# neorv32 register map
Vendor: github.com/stnolting/neorv32; Series: RISC-V; File version: 1.13.7
The NEORV32 RISC-V Processor
CPU: other r1p0, little endian, MPU, FPU, I-cache, D-cache, ITCM, DTCM, 4 interrupt priority bits
Address unit: 16 bits
Registers are 32-bit, read-write, reset 0x0 unless marked. A register's access mark holds for its fields unless they carry their own. Offsets are from the block's base; lines under a group give offsets from that group; [hi:lo] are bit positions; {n}, {i} and the like mark numbered series; 'fields as' and 'values as' point back to an identical list; <NAME> marks a mode.

## Memory map
0xFFEA0000 TWD size 0x8 — Two-wire device controller
0xFFEB0000 CFS size 0x10000 — Custom functions subsystem
0xFFEC0000 SLINK size 0x10 — Stream Link Interface
0xFFED0000 DMA size 0x10 — Direct memory access controller
0xFFEF0000 SMC size 0x8 — Serial Memory Controller
0xFFF00000 PWM size 0x100 — Pulse-width modulation controller
0xFFF10000 GPTMR size 0x100 — General purpose timer
0xFFF20000 ONEWIRE size 0x8 — 1-Wire Interface Controller
0xFFF30000 TRACEBUF size 0x10 — Execution Trace Buffer
0xFFF40000 CLINT size 0x10000 — Core local interruptor
0xFFF50000 UART0 size 0x10 — Primary universal asynchronous receiver and transmitter
0xFFF60000 UART1 size 0x10 — Secondary universal asynchronous receiver and transmitter
0xFFF70000 SDI size 0x8 — Serial data interface controller
0xFFF80000 SPI size 0x8 — Serial peripheral interface controller
0xFFF90000 TWI size 0x8 — Two-wire interface controller
0xFFFA0000 TRNG size 0x8 — True random number generator
0xFFFB0000 WDT size 0x8 — Watchdog timer
0xFFFC0000 GPIO size 0x20 — General purpose input/output port
0xFFFD0000 NEOLED size 0x10 — Smart LED hardware interface
0xFFFE0000 SYSINFO size 0x10 — System configuration information memory

## Interrupts
1 CFS_FIRQ (CFS)
2 UART0_FIRQ (UART0)
3 UART1_FIRQ (UART1)
4 TWD_FIRQ (TWD)
5 TRACEBUF_FIRQ (TRACEBUF)
6 SPI_FIRQ (SPI)
7 TWI_FIRQ (TWI)
8 GPIO_FIRQ (GPIO)
9 NEOLED_FIRQ (NEOLED)
10 DMA_FIRQ (DMA)
11 SDI_FIRQ (SDI)
12 GPTMR_FIRQ (GPTMR)
13 ONEWIRE_FIRQ (ONEWIRE)
14 SLINK_FIRQ (SLINK)
15 TRNG_FIRQ (TRNG)

## CFS — Custom functions subsystem
Base 0xFFEB0000
{0x0+4i} REG{i} (i=0..63) — User-defined

## SDI — Serial data interface controller
Base 0xFFF70000
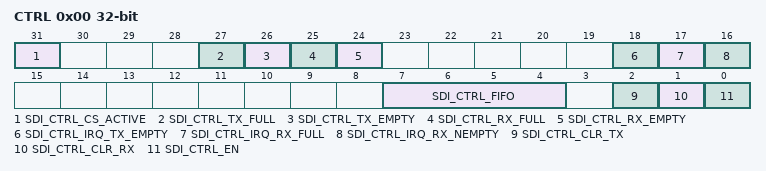
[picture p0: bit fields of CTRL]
0x00 CTRL — Control register
  [31] SDI_CTRL_CS_ACTIVE ro — Chip-select line is active when set
  [27] SDI_CTRL_TX_FULL ro — TX FIFO full
  [26] SDI_CTRL_TX_EMPTY ro — TX FIFO empty
  [25] SDI_CTRL_RX_FULL ro — RX FIFO full
  [24] SDI_CTRL_RX_EMPTY ro — RX FIFO empty
  [18] SDI_CTRL_IRQ_TX_EMPTY — Fire interrupt if TX FIFO is empty
  [17] SDI_CTRL_IRQ_RX_FULL — Fire interrupt if RX FIFO is full
  [16] SDI_CTRL_IRQ_RX_NEMPTY — Fire interrupt if RX FIFO is not empty
  [7:4] SDI_CTRL_FIFO — log2(FIFO size)
  [2] SDI_CTRL_CLR_TX wo — Clear TX FIFO, flag auto-clears
  [1] SDI_CTRL_CLR_RX wo — Clear RX FIFO, flag auto-clears
  [0] SDI_CTRL_EN — SDI enable
0x04 DATA read-modifies — RX/TX data register
  [7:0] SDI_DATA — RX data / TX data (via FIFOs)

## SLINK — Stream Link Interface
Base 0xFFEC0000
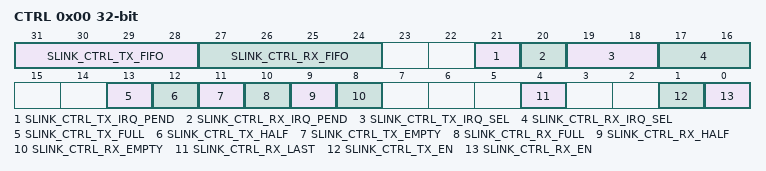
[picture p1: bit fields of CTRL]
0x00 CTRL — Control and status register
  [31:28] SLINK_CTRL_TX_FIFO ro — log2(TX FIFO size)
  [27:24] SLINK_CTRL_RX_FIFO ro — log2(RX FIFO size)
  [21] SLINK_CTRL_TX_IRQ_PEND ro — TX interrupt active
  [20] SLINK_CTRL_RX_IRQ_PEND ro — RX interrupt active
  [19:18] SLINK_CTRL_TX_IRQ_SEL — TX interrupt select
  [17:16] SLINK_CTRL_RX_IRQ_SEL — RX interrupt select
  [13] SLINK_CTRL_TX_FULL ro — TX FIFO full
  [12] SLINK_CTRL_TX_HALF ro — TX FIFO at least half full
  [11] SLINK_CTRL_TX_EMPTY ro — TX FIFO empty
  [10] SLINK_CTRL_RX_FULL ro — RX FIFO full
  [9] SLINK_CTRL_RX_HALF ro — RX FIFO at least half full
  [8] SLINK_CTRL_RX_EMPTY ro — RX FIFO empty
  [4] SLINK_CTRL_RX_LAST ro — Top of RX FIFO is last word of package
  [1] SLINK_CTRL_TX_EN — Enable transmitter
  [0] SLINK_CTRL_RX_EN — Enable receiver
0x04 ROUTE — Routing information
  [3:0] SLINK_ROUTE — RX TOP word's source / TX destination address/ID
0x08 DATA read-modifies — RX/TX data register
0x0C DATA2 read-modifies — TX data register (plus TX end-of-stream delimiter)

## Notices in the file
Copyright (c) NEORV32 contributors.
Copyright (c) Stephan Nolting. All rights reserved.
Licensed under the BSD-3-Clause license, see LICENSE for details.
SPDX-License-Identifier: BSD-3-Clause
